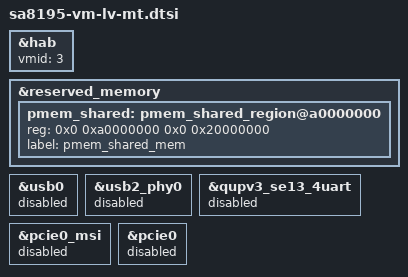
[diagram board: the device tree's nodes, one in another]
/ {
	/delete-node/ cpus;
};

&hab {
	vmid = <3>;
};

&reserved_memory {
	pmem_shared: pmem_shared_region@a0000000 {
		reg = <0x0 0xa0000000 0x0 0x20000000>;
		label = "pmem_shared_mem";
	};
};

#include "display/quin-vm-display-lv.dtsi"

&usb0 {
	status = "disabled";
};

&usb2_phy0 {
	status = "disabled";
};

&qupv3_se13_4uart {
	status = "disabled";
};

&pcie0_msi {
	status = "disabled";
};

&pcie0 {
	status = "disabled";
};
